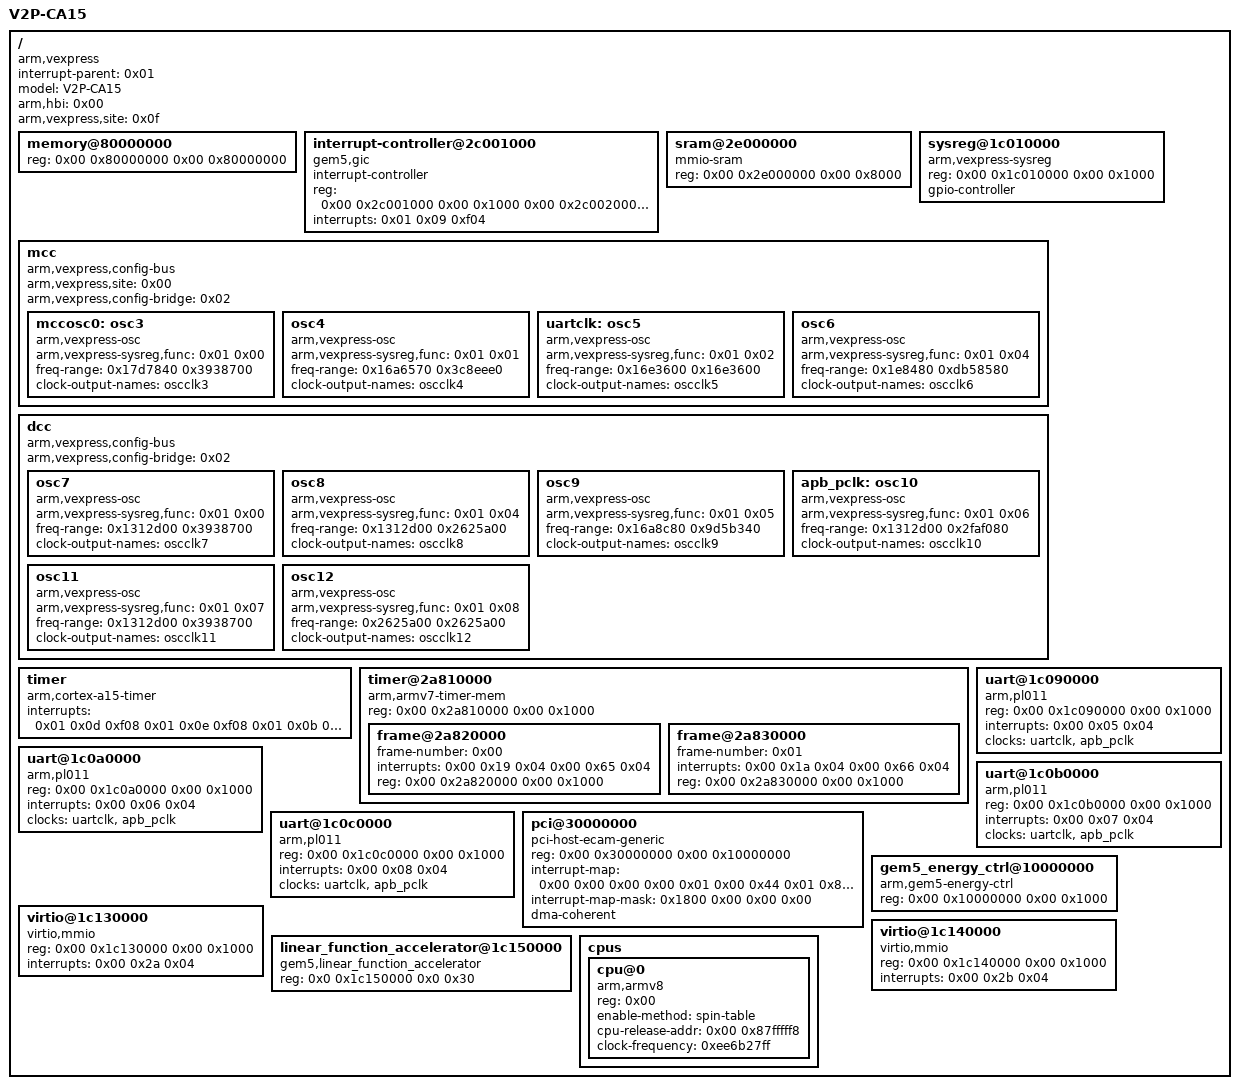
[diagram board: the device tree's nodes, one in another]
/dts-v1/;

/ {
	#address-cells = <0x02>;
	#size-cells = <0x02>;
	interrupt-parent = <0x01>;
	compatible = "arm,vexpress";
	model = "V2P-CA15";
	arm,hbi = <0x00>;
	arm,vexpress,site = <0x0f>;

	memory@80000000 {
		device_type = "memory";
		reg = <0x00 0x80000000 0x00 0x80000000>;
	};

	interrupt-controller@2c001000 {
		compatible = "gem5,gic\0arm,cortex-a15-gic\0arm,cortex-a9-gic";
		#interrupt-cells = <0x03>;
		#address-cells = <0x00>;
		interrupt-controller;
		reg = <0x00 0x2c001000 0x00 0x1000 0x00 0x2c002000 0x00 0x1000 0x00 0x2c004000 0x00 0x2000 0x00 0x2c006000 0x00 0x2000>;
		interrupts = <0x01 0x09 0xf04>;
		phandle = <0x01>;
	};

	sram@2e000000 {
		compatible = "mmio-sram";
		reg = <0x00 0x2e000000 0x00 0x8000>;
		#address-cells = <0x02>;
		#size-cells = <0x02>;
		ranges = <0x00 0x00 0x00 0x2e000000 0x00 0x8000>;
	};

	sysreg@1c010000 {
		compatible = "arm,vexpress-sysreg";
		reg = <0x00 0x1c010000 0x00 0x1000>;
		gpio-controller;
		#gpio-cells = <0x02>;
		phandle = <0x02>;
	};

	mcc {
		compatible = "arm,vexpress,config-bus";
		arm,vexpress,site = <0x00>;
		arm,vexpress,config-bridge = <0x02>;

		mccosc0: osc3 {
			compatible = "arm,vexpress-osc";
			arm,vexpress-sysreg,func = <0x01 0x00>;
			#clock-cells = <0x00>;
			freq-range = <0x17d7840 0x3938700>;
			clock-output-names = "oscclk3";
		};

		osc4 {
			compatible = "arm,vexpress-osc";
			arm,vexpress-sysreg,func = <0x01 0x01>;
			#clock-cells = <0x00>;
			freq-range = <0x16a6570 0x3c8eee0>;
			clock-output-names = "oscclk4";
			phandle = <0x04>;
		};

		uartclk: osc5 {
			compatible = "arm,vexpress-osc";
			arm,vexpress-sysreg,func = <0x01 0x02>;
			#clock-cells = <0x00>;
			freq-range = <0x16e3600 0x16e3600>;
			clock-output-names = "oscclk5";
			phandle = <0x05>;
		};

		osc6 {
			compatible = "arm,vexpress-osc";
			arm,vexpress-sysreg,func = <0x01 0x04>;
			#clock-cells = <0x00>;
			freq-range = <0x1e8480 0xdb58580>;
			clock-output-names = "oscclk6";
			phandle = <0x06>;
		};
	};

	dcc {
		compatible = "arm,vexpress,config-bus";
		arm,vexpress,config-bridge = <0x02>;

		osc7 {
			compatible = "arm,vexpress-osc";
			arm,vexpress-sysreg,func = <0x01 0x00>;
			#clock-cells = <0x00>;
			freq-range = <0x1312d00 0x3938700>;
			clock-output-names = "oscclk7";
			phandle = <0x07>;
		};

		osc8 {
			compatible = "arm,vexpress-osc";
			arm,vexpress-sysreg,func = <0x01 0x04>;
			#clock-cells = <0x00>;
			freq-range = <0x1312d00 0x2625a00>;
			clock-output-names = "oscclk8";
			phandle = <0x08>;
		};

		osc9 {
			compatible = "arm,vexpress-osc";
			arm,vexpress-sysreg,func = <0x01 0x05>;
			#clock-cells = <0x00>;
			freq-range = <0x16a8c80 0x9d5b340>;
			clock-output-names = "oscclk9";
			phandle = <0x09>;
		};

		apb_pclk: osc10 {
			compatible = "arm,vexpress-osc";
			arm,vexpress-sysreg,func = <0x01 0x06>;
			#clock-cells = <0x00>;
			freq-range = <0x1312d00 0x2faf080>;
			clock-output-names = "oscclk10";
		};

		osc11 {
			compatible = "arm,vexpress-osc";
			arm,vexpress-sysreg,func = <0x01 0x07>;
			#clock-cells = <0x00>;
			freq-range = <0x1312d00 0x3938700>;
			clock-output-names = "oscclk11";
			phandle = <0x0b>;
		};

		osc12 {
			compatible = "arm,vexpress-osc";
			arm,vexpress-sysreg,func = <0x01 0x08>;
			#clock-cells = <0x00>;
			freq-range = <0x2625a00 0x2625a00>;
			clock-output-names = "oscclk12";
			phandle = <0x0c>;
		};
	};

	timer {
		compatible = "arm,cortex-a15-timer\0arm,armv7-timer\0arm,armv8-timer";
		interrupts = <0x01 0x0d 0xf08 0x01 0x0e 0xf08 0x01 0x0b 0xf08 0x01 0x0a 0xf08 0x01 0x0c 0xf08>;
	};

	timer@2a810000 {
		reg = <0x00 0x2a810000 0x00 0x1000>;
		compatible = "arm,armv7-timer-mem";
		#address-cells = <0x02>;
		#size-cells = <0x02>;
		ranges;

		frame@2a820000 {
			frame-number = <0x00>;
			interrupts = <0x00 0x19 0x04 0x00 0x65 0x04>;
			reg = <0x00 0x2a820000 0x00 0x1000>;
		};

		frame@2a830000 {
			frame-number = <0x01>;
			interrupts = <0x00 0x1a 0x04 0x00 0x66 0x04>;
			reg = <0x00 0x2a830000 0x00 0x1000>;
		};
	};

	uart@1c090000 {
		reg = <0x00 0x1c090000 0x00 0x1000>;
		interrupts = <0x00 0x05 0x04>;
		compatible = "arm,pl011\0arm,primecell";
		clocks = <&uartclk &apb_pclk>;
		clock-names = "uartclk\0apb_pclk";
	};

	uart@1c0a0000 {
		reg = <0x00 0x1c0a0000 0x00 0x1000>;
		interrupts = <0x00 0x06 0x04>;
		compatible = "arm,pl011\0arm,primecell";
		clocks = <&uartclk &apb_pclk>;
		clock-names = "uartclk\0apb_pclk";
	};

	uart@1c0b0000 {
		reg = <0x00 0x1c0b0000 0x00 0x1000>;
		interrupts = <0x00 0x07 0x04>;
		compatible = "arm,pl011\0arm,primecell";
		clocks = <&uartclk &apb_pclk>;
		clock-names = "uartclk\0apb_pclk";
	};

	uart@1c0c0000 {
		reg = <0x00 0x1c0c0000 0x00 0x1000>;
		interrupts = <0x00 0x08 0x04>;
		compatible = "arm,pl011\0arm,primecell";
		clocks = <&uartclk &apb_pclk>;
		clock-names = "uartclk\0apb_pclk";
	};

	pci@30000000 {
		compatible = "pci-host-ecam-generic";
		device_type = "pci";
		#address-cells = <0x03>;
		#size-cells = <0x02>;
		#interrupt-cells = <0x01>;
		reg = <0x00 0x30000000 0x00 0x10000000>;
		ranges = <0x1000000 0x00 0x00 0x00 0x2f000000 0x00 0x10000 0x2000000 0x00 0x00 0x00 0x40000000 0x00 0x40000000>;
		interrupt-map = <0x00 0x00 0x00 0x00 0x01 0x00 0x44 0x01 0x800 0x00 0x00 0x00 0x01 0x00 0x45 0x01 0x1000 0x00 0x00 0x00 0x01 0x00 0x46 0x01 0x1800 0x00 0x00 0x00 0x01 0x00 0x47 0x01>;
		interrupt-map-mask = <0x1800 0x00 0x00 0x00>;
		dma-coherent;
	};

	gem5_energy_ctrl@10000000 {
		reg = <0x00 0x10000000 0x00 0x1000>;
		compatible = "arm,gem5-energy-ctrl";
	};

	virtio@1c130000 {
		reg = <0x00 0x1c130000 0x00 0x1000>;
		interrupts = <0x00 0x2a 0x04>;
		compatible = "virtio,mmio";
	};

	virtio@1c140000 {
		reg = <0x00 0x1c140000 0x00 0x1000>;
		interrupts = <0x00 0x2b 0x04>;
		compatible = "virtio,mmio";
	};

	linear_function_accelerator@1c150000 {
		compatible = "gem5,linear_function_accelerator";
		reg = <0x0 0x1c150000 0x0 0x30>;
		status = "okay";
	};

	cpus {
		#address-cells = <0x01>;
		#size-cells = <0x00>;

		cpu@0 {
			device_type = "cpu";
			compatible = "arm,armv8";
			reg = <0x00>;
			enable-method = "spin-table";
			cpu-release-addr = <0x00 0x87fffff8>;
			clock-frequency = <0xee6b27ff>;
			phandle = <0x0f>;
		};
	};
};
